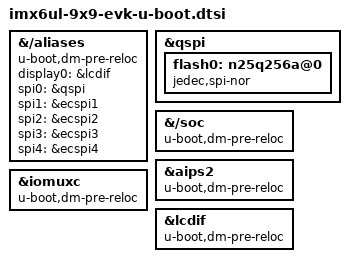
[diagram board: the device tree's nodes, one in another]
// SPDX-License-Identifier: GPL-2.0+
/*
 * Copyright 2018, 2023 NXP
 */

&{/aliases} {
	u-boot,dm-pre-reloc;
	display0 = &lcdif;

	spi0 = &qspi;
	spi1 = &ecspi1;
	spi2 = &ecspi2;
	spi3 = &ecspi3;
	spi4 = &ecspi4;
};

&qspi {
	flash0: n25q256a@0 {
		compatible = "jedec,spi-nor";
	};
};

&{/soc} {
	u-boot,dm-pre-reloc;
};

&aips2 {
	u-boot,dm-pre-reloc;
};

&iomuxc {
	u-boot,dm-pre-reloc;
};

&lcdif {
	u-boot,dm-pre-reloc;
};
